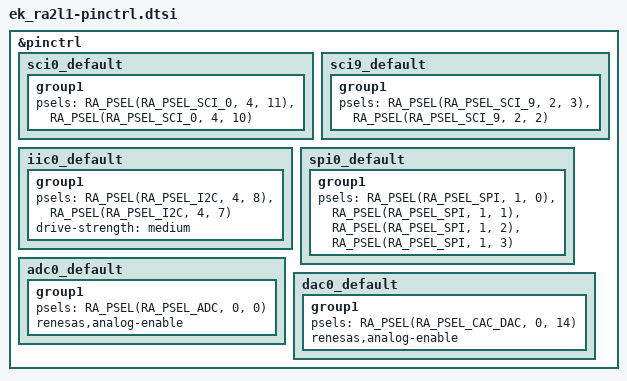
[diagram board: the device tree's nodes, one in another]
/*
 * Copyright (c) 2024-2025 Renesas Electronics Corporation
 * SPDX-License-Identifier: Apache-2.0
 */

&pinctrl {
	sci0_default: sci0_default {
		group1 {
			/* tx rx */
			psels = <RA_PSEL(RA_PSEL_SCI_0, 4, 11)>,
				<RA_PSEL(RA_PSEL_SCI_0, 4, 10)>;
		};
	};

	sci9_default: sci9_default {
		group1 {
			/* tx rx */
			psels = <RA_PSEL(RA_PSEL_SCI_9, 2, 3)>,
				<RA_PSEL(RA_PSEL_SCI_9, 2, 2)>;
		};
	};

	iic0_default: iic0_default {
		group1 {
			/* SCL0 SDA0 */
			psels = <RA_PSEL(RA_PSEL_I2C, 4, 8)>,
				<RA_PSEL(RA_PSEL_I2C, 4, 7)>;
			drive-strength = "medium";
		};
	};

	spi0_default: spi0_default {
		group1 {
			/* MISO MOSI RSPCK SSL */
			psels = <RA_PSEL(RA_PSEL_SPI, 1, 0)>,
				<RA_PSEL(RA_PSEL_SPI, 1, 1)>,
				<RA_PSEL(RA_PSEL_SPI, 1, 2)>,
				<RA_PSEL(RA_PSEL_SPI, 1, 3)>;
		};
	};

	adc0_default: adc0_default {
		group1 {
			/* input */
			psels = <RA_PSEL(RA_PSEL_ADC, 0, 0)>;
			renesas,analog-enable;
		};
	};

	dac0_default: dac0_default {
		group1 {
			/* output */
			psels = <RA_PSEL(RA_PSEL_CAC_DAC, 0, 14)>;
			renesas,analog-enable;
		};
	};
};
